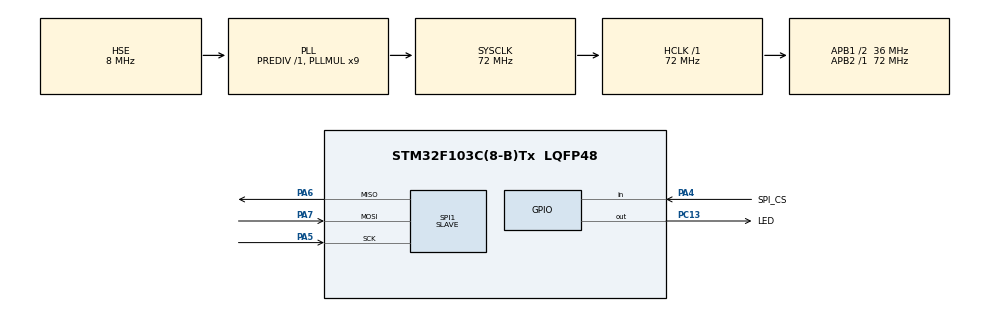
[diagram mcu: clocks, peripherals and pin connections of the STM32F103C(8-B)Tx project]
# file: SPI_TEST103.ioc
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Mcu.Family=STM32F1
Mcu.Name=STM32F103C(8-B)Tx
Mcu.Package=LQFP48
NVIC.PriorityGroup=NVIC_PRIORITYGROUP_4
NVIC.SPI1_IRQn=true\:0\:0\:false\:false\:true\:true\:true\:true
PA4.GPIO_Label=SPI_CS
PA4.GPIO_PuPd=GPIO_NOPULL
PA4.Signal=GPIO_Input
PA5.Mode=Full_Duplex_Slave
PA5.Signal=SPI1_SCK
PA6.Mode=Full_Duplex_Slave
PA6.Signal=SPI1_MISO
PA7.Mode=Full_Duplex_Slave
PA7.Signal=SPI1_MOSI
PC13-TAMPER-RTC.GPIO_Label=LED
PC13-TAMPER-RTC.GPIO_Speed=GPIO_SPEED_FREQ_HIGH
PC13-TAMPER-RTC.Signal=GPIO_Output
PD0-OSC_IN.Mode=HSE-External-Oscillator
PD0-OSC_IN.Signal=RCC_OSC_IN
PD1-OSC_OUT.Mode=HSE-External-Oscillator
PD1-OSC_OUT.Signal=RCC_OSC_OUT
ProjectManager.HeapSize=0x200
ProjectManager.StackSize=0x400
ProjectManager.TargetToolchain=MDK-ARM V5.32
RCC.AHBFreq_Value=72000000
RCC.APB1CLKDivider=RCC_HCLK_DIV2
RCC.APB1Freq_Value=36000000
RCC.APB1TimFreq_Value=72000000
RCC.APB2Freq_Value=72000000
RCC.APB2TimFreq_Value=72000000
RCC.HCLKFreq_Value=72000000
RCC.PLLMUL=RCC_PLL_MUL9
RCC.PLLSourceVirtual=RCC_PLLSOURCE_HSE
RCC.SYSCLKFreq_VALUE=72000000
RCC.SYSCLKSource=RCC_SYSCLKSOURCE_PLLCLK
RCC.USBFreq_Value=72000000
SPI1.CLKPhase=SPI_PHASE_2EDGE
SPI1.CLKPolarity=SPI_POLARITY_HIGH
SPI1.DataSize=SPI_DATASIZE_16BIT
SPI1.Direction=SPI_DIRECTION_2LINES
SPI1.Mode=SPI_MODE_SLAVE
SPI1.VirtualType=VM_SLAVE
VP_SYS_VS_ND.Mode=No_Debug
board=custom

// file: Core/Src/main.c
/* USER CODE BEGIN Header */
/**
  ******************************************************************************
  * @file           : main.c
  * @brief          : Main program body
  ******************************************************************************
  * @attention
  *
  * Copyright (c) 2025 STMicroelectronics.
  * All rights reserved.
  *
  * This software is licensed under terms that can be found in the LICENSE file
  * in the root directory of this software component.
  * If no LICENSE file comes with this software, it is provided AS-IS.
  *
  ******************************************************************************
  */
/* USER CODE END Header */
#include "main.h"
#include "spi.h"
#include "gpio.h"

/* USER CODE BEGIN PV */
uint16_t spi_rxData = 0;
/* USER CODE END PV */

void SystemClock_Config(void);

int main(void)
{

  /* MCU Configuration--------------------------------------------------------*/

  /* Reset of all peripherals, Initializes the Flash interface and the Systick. */
  HAL_Init();

  /* Configure the system clock */
  SystemClock_Config();

  /* Initialize all configured peripherals */
  MX_GPIO_Init();
  MX_SPI1_Init();

  /* Infinite loop */
  while (1)
  {

//    /* USER CODE BEGIN 3 */
//if (HAL_GPIO_ReadPin(SPI_CS_GPIO_Port, SPI_CS_Pin) == GPIO_PIN_RESET) {
//    // 当CS被拉低时，从从设备读取16位数据
//    uint16_t spi_rxData = spi1_SLAVE_read_bit16();
//
//    // 检查读取的数据是否为0x8000
//    if (spi_rxData == 0x8000) {
//        uint16_t txdata = 0xAACC;
//        // 发送完整的16位数据
//        HAL_StatusTypeDef status = HAL_SPI_Transmit(&hspi1, (uint8_t *)&txdata, 2, 1000);
//
//        // 检查SPI传输状态
//        if (status != HAL_OK) {
//            // 处理错误
//            Error_Handler();
//        }
//    }
//}
		HAL_Delay(5000);
		HAL_GPIO_TogglePin(LED_GPIO_Port,LED_Pin);
  }
  /* USER CODE END 3 */
}

void SystemClock_Config(void)
{
  RCC_OscInitTypeDef RCC_OscInitStruct = {0};
  RCC_ClkInitTypeDef RCC_ClkInitStruct = {0};

  /** Initializes the RCC Oscillators according to the specified parameters
  * in the RCC_OscInitTypeDef structure.
  */
  RCC_OscInitStruct.OscillatorType = RCC_OSCILLATORTYPE_HSE;
  RCC_OscInitStruct.HSEState = RCC_HSE_ON;
  RCC_OscInitStruct.HSEPredivValue = RCC_HSE_PREDIV_DIV1;
  RCC_OscInitStruct.HSIState = RCC_HSI_ON;
  RCC_OscInitStruct.PLL.PLLState = RCC_PLL_ON;
  RCC_OscInitStruct.PLL.PLLSource = RCC_PLLSOURCE_HSE;
  RCC_OscInitStruct.PLL.PLLMUL = RCC_PLL_MUL9;
  if (HAL_RCC_OscConfig(&RCC_OscInitStruct) != HAL_OK)
  {
    Error_Handler();
  }

  /** Initializes the CPU, AHB and APB buses clocks
  */
  RCC_ClkInitStruct.ClockType = RCC_CLOCKTYPE_HCLK|RCC_CLOCKTYPE_SYSCLK
                              |RCC_CLOCKTYPE_PCLK1|RCC_CLOCKTYPE_PCLK2;
  RCC_ClkInitStruct.SYSCLKSource = RCC_SYSCLKSOURCE_PLLCLK;
  RCC_ClkInitStruct.AHBCLKDivider = RCC_SYSCLK_DIV1;
  RCC_ClkInitStruct.APB1CLKDivider = RCC_HCLK_DIV2;
  RCC_ClkInitStruct.APB2CLKDivider = RCC_HCLK_DIV1;

  if (HAL_RCC_ClockConfig(&RCC_ClkInitStruct, FLASH_LATENCY_2) != HAL_OK)
  {
    Error_Handler();
  }
}

void Error_Handler(void)
{
  __disable_irq();
  while (1)
  {
  }
}
